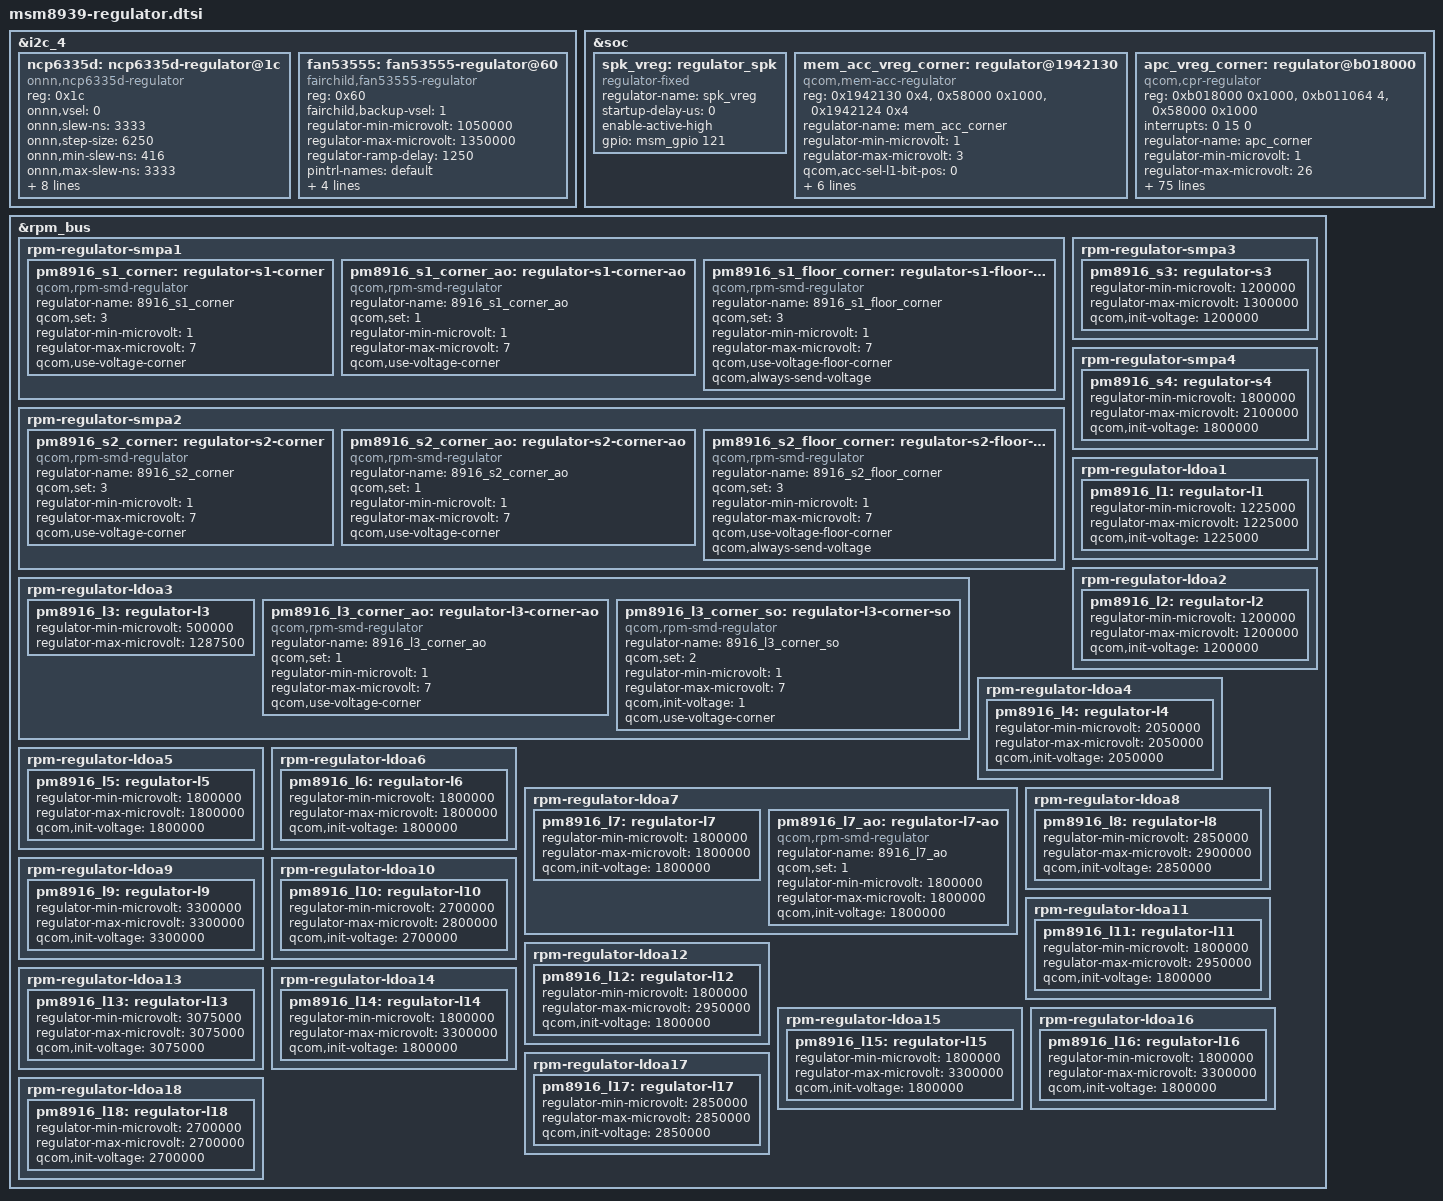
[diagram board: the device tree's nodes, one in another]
/* Copyright (c) 2014, The Linux Foundation. All rights reserved.
 *
 * This program is free software; you can redistribute it and/or modify
 * it under the terms of the GNU General Public License version 2 and
 * only version 2 as published by the Free Software Foundation.
 *
 * This program is distributed in the hope that it will be useful,
 * but WITHOUT ANY WARRANTY; without even the implied warranty of
 * MERCHANTABILITY or FITNESS FOR A PARTICULAR PURPOSE.  See the
 * GNU General Public License for more details.
 */

/* External I2C controlled buck regulators */

&i2c_4 {
	ncp6335d: ncp6335d-regulator@1c {
		compatible = "onnn,ncp6335d-regulator";
		reg = <0x1c>;
		onnn,vsel = <0>;
		onnn,slew-ns = <3333>;
		onnn,step-size = <6250>;
		onnn,min-slew-ns = <416>;
		onnn,max-slew-ns = <3333>;
		regulator-min-microvolt = <1050000>;
		regulator-max-microvolt = <1350000>;
		onnn,min-setpoint = <600000>;
		pintrl-names = "default";
		pinctrl-0 = <&ext_buck_vsel_default>;
		onnn,vsel-gpio = <&msm_gpio 111 1>;
		onnn,discharge-enable;
		onnn,restore-reg;
	};

	fan53555: fan53555-regulator@60 {
		compatible = "fairchild,fan53555-regulator";
		reg = <0x60>;
		fairchild,backup-vsel = <1>;
		regulator-min-microvolt = <1050000>;
		regulator-max-microvolt = <1350000>;
		regulator-ramp-delay = <1250>;
		pintrl-names = "default";
		pinctrl-0 = <&ext_buck_vsel_default>;
		fairchild,vsel-gpio = <&msm_gpio 111 1>;
		fairchild,restore-reg;
		fairchild,disable-suspend;
	};
};

/* Memory accelerator and CPR controlled regulators */

&soc {
	spk_vreg: regulator_spk {
		compatible = "regulator-fixed";
		regulator-name = "spk_vreg";
		startup-delay-us = <0>;
		enable-active-high;
		gpio = <&msm_gpio 121 0>;
	};

	mem_acc_vreg_corner: regulator@1942130 {
		compatible = "qcom,mem-acc-regulator";
		reg = <0x1942130 0x4>, <0x58000 0x1000>, <0x1942124 0x4>;
		reg-names = "acc-sel-l1", "efuse_addr", "acc-l2-custom";
		regulator-name = "mem_acc_corner";
		regulator-min-microvolt = <1>;
		regulator-max-microvolt = <3>;

		qcom,acc-sel-l1-bit-pos = <0>;
		qcom,corner-acc-map = <0 0 1>;
		qcom,l2-acc-custom-data = <0x0 0x0 0x3000>;

		qcom,override-acc-fuse-sel = <0 30 1 1 0>;
		qcom,override-corner-acc-map = <0 1 1>;
		qcom,override-l2-acc-custom-data = <0x0 0x3000 0x3000>;
	};

	apc_vreg_corner: regulator@b018000 {
		compatible = "qcom,cpr-regulator";
		reg = <0xb018000 0x1000>, <0xb011064 4>, <0x58000 0x1000>;
		reg-names = "rbcpr", "rbcpr_clk", "efuse_addr";
		interrupts = <0 15 0>;
		regulator-name = "apc_corner";
		regulator-min-microvolt = <1>;
		regulator-max-microvolt = <26>;

		qcom,cpr-fuse-corners = <3>;
		qcom,cpr-voltage-ceiling = <1050000 1150000 1350000>;
		qcom,cpr-voltage-floor = <1050000 1050000 1137500>;
		vdd-apc-supply = <&ncp6335d>;

		qcom,vdd-mx-corner-map = <4 5 7>;
		qcom,vdd-mx-vmin-method = <4>;
		vdd-mx-supply = <&pm8916_l3_corner_ao>;
		qcom,vdd-mx-vmax = <7>;

		mem-acc-supply = <&mem_acc_vreg_corner>;

		qcom,cpr-ref-clk = <19200>;
		qcom,cpr-timer-delay = <5000>;
		qcom,cpr-timer-cons-up = <0>;
		qcom,cpr-timer-cons-down = <2>;
		qcom,cpr-irq-line = <0>;
		qcom,cpr-step-quotient = <13>;
		qcom,cpr-up-threshold = <0>;
		qcom,cpr-down-threshold = <3>;
		qcom,cpr-idle-clocks = <15>;
		qcom,cpr-gcnt-time = <1>;
		qcom,vdd-apc-step-up-limit = <1>;
		qcom,vdd-apc-step-down-limit = <1>;
		qcom,cpr-apc-volt-step = <6250>;

		qcom,cpr-fuse-row = <27 0>;
		qcom,cpr-fuse-target-quot = <42 24 6>;
		qcom,cpr-fuse-ro-sel = <54 54 54>;
		qcom,cpr-quot-min-diff = <0>;
		qcom,cpr-init-voltage-ref = <1050000 1150000 1350000>;
		qcom,cpr-fuse-init-voltage =
					<27 36 6 0>,
					<27 18 6 0>,
					<27 0 6 0>;
		qcom,cpr-init-voltage-step = <10000>;
		qcom,cpr-scaled-init-voltage-as-ceiling;
		qcom,cpr-corner-map = <1 1 1 2 2 2 2 2 2 2 2 2 2 2 3 3 3 3 3 3
					3 3 3 3 3 3>;
		qcom,cpr-corner-frequency-map =
					<1 200000000>,
					<2 345600000>,
					<3 400000000>,
					<4 422400000>,
					<5 499200000>,
					<6 533330000>,
					<7 652800000>,
					<8 729600000>,
					<9 800000000>,
					<10 806400000>,
					<11 883200000>,
					<12 960000000>,
					<13 1036800000>,
					<14 1113600000>,
					<15 1190400000>,
					<16 1267200000>,
					<17 1344000000>,
					<18 1420800000>,
					<19 1497600000>,
					<20 1536000000>,
					<21 1574400000>,
					<22 1612800000>,
					<23 1632000000>,
					<24 1651200000>,
					<25 1689600000>,
					<26 1708800000>;
		qcom,speed-bin-fuse-sel = <1 34 3 0>;
		qcom,cpr-speed-bin-max-corners =
					<0 0 3 14 17>,
					<0 1 3 14 17>,
					<2 0 3 14 19>,
					<2 1 3 14 19>,
					<4 0 3 14 26>,
					<4 1 3 14 26>,
					<5 0 3 14 24>,
					<5 1 3 14 24>;
		qcom,cpr-quot-adjust-scaling-factor-max = <900>;
		qcom,pvs-version-fuse-sel = <0 45 1 0>;
		qcom,cpr-fuse-version-map =
			<2          0 0xffffffff 0xffffffff
					0xffffffff 0xffffffff>,
			<2          1 0xffffffff 0xffffffff
					0xffffffff 0xffffffff>,
			<0xffffffff 0 0xffffffff 0xffffffff
					0xffffffff 0xffffffff>,
			<0xffffffff 1 0xffffffff 0xffffffff
					0xffffffff 0xffffffff>;
		qcom,cpr-init-voltage-adjustment =
					<0 50000 0>,
					<0 20000 0>,
					<0 50000 0>,
					<0 20000 0>;
		qcom,cpr-quotient-adjustment =
					<0 104  (-41)>,
					<0  41  (-41)>,
					<0 104  (-41)>,
					<0  41  (-41)>;
		qcom,cpr-virtual-corner-quotient-adjustment =
			<0 0 0 (-104) (-104) (-104) (-104) (-104) (-104) (-104)
			 (-104) (-104) (-41) 0 0 0 0 0 0 0 0 72 0 0 0 0>,
			<0 0 0 (-104) (-104) (-104) (-104) (-104) (-104) (-104)
			 (-104) (-41) (-41) 0 0 0 0 0 0 0 0 72 0 0 0 0>,
			<0 0 0 (-104) (-104) (-104) (-104) (-104) (-104) (-104)
			 (-104) (-104) (-41) 0 0 0 0 0 0 0 0 0 0 0 0 0>,
			<0 0 0 (-104) (-104) (-104) (-104) (-104) (-104) (-104)
			 (-104) (-41) (-41) 0 0 0 0 0 0 0 0 0 0 0 0 0>;
		qcom,cpr-virtual-corner-init-voltage-adjustment =
			<0 0 0 0 0 0 0 0 0 0 0 0 0 0 0 0 0 0 0 0 0 35000 0 0 0 0>,
			<0 0 0 0 0 0 0 0 0 0 0 0 0 0 0 0 0 0 0 0 0 35000 0 0 0 0>,
			<0 0 0 0 0 0 0 0 0 0 0 0 0 0 0 0 0 0 0 0 0     0 0 0 0 0>,
			<0 0 0 0 0 0 0 0 0 0 0 0 0 0 0 0 0 0 0 0 0     0 0 0 0 0>;
		qcom,cpr-voltage-floor-override =
			<0xffffffff 0xffffffff 1050000 1050000 1050000
			1050000 1050000 1050000 1050000 1050000 1050000
			1050000 1050000 1050000 1050000 1100000 1137500
			1137500 1137500 1137500 1137500 1137500 1137500
			1137500 1137500 1137500 1137500 1137500>;
		qcom,cpr-enable;
	};
};

/* RPM controlled regulators */

&rpm_bus {
	/* PM8916 S1 VDD_CX for MODEM/NAV/Crypto/MODEM Q6 */
	rpm-regulator-smpa1 {
		status = "okay";
		pm8916_s1_corner: regulator-s1-corner {
			compatible = "qcom,rpm-smd-regulator";
			regulator-name = "8916_s1_corner";
			qcom,set = <3>;
			regulator-min-microvolt = <1>;
			regulator-max-microvolt = <7>;
			qcom,use-voltage-corner;
		};
		pm8916_s1_corner_ao: regulator-s1-corner-ao {
			compatible = "qcom,rpm-smd-regulator";
			regulator-name = "8916_s1_corner_ao";
			qcom,set = <1>;
			regulator-min-microvolt = <1>;
			regulator-max-microvolt = <7>;
			qcom,use-voltage-corner;
		};
		pm8916_s1_floor_corner: regulator-s1-floor-corner {
			compatible = "qcom,rpm-smd-regulator";
			regulator-name = "8916_s1_floor_corner";
			qcom,set = <3>;
			regulator-min-microvolt = <1>;
			regulator-max-microvolt = <7>;
			qcom,use-voltage-floor-corner;
			qcom,always-send-voltage;
		};
	};

	/* PM8916 S2 VDD_CX for Venus/TOP/GFX/Pronto/MDSS*/
	rpm-regulator-smpa2 {
		status = "okay";
		pm8916_s2_corner: regulator-s2-corner {
			compatible = "qcom,rpm-smd-regulator";
			regulator-name = "8916_s2_corner";
			qcom,set = <3>;
			regulator-min-microvolt = <1>;
			regulator-max-microvolt = <7>;
			qcom,use-voltage-corner;
		};
		pm8916_s2_corner_ao: regulator-s2-corner-ao {
			compatible = "qcom,rpm-smd-regulator";
			regulator-name = "8916_s2_corner_ao";
			qcom,set = <1>;
			regulator-min-microvolt = <1>;
			regulator-max-microvolt = <7>;
			qcom,use-voltage-corner;
		};
		pm8916_s2_floor_corner: regulator-s2-floor-corner {
			compatible = "qcom,rpm-smd-regulator";
			regulator-name = "8916_s2_floor_corner";
			qcom,set = <3>;
			regulator-min-microvolt = <1>;
			regulator-max-microvolt = <7>;
			qcom,use-voltage-floor-corner;
			qcom,always-send-voltage;
		};
	};

	rpm-regulator-smpa3 {
		status = "okay";
		pm8916_s3: regulator-s3 {
			regulator-min-microvolt = <1200000>;
			regulator-max-microvolt = <1300000>;
			qcom,init-voltage = <1200000>;
			status = "okay";
		};
	};

	rpm-regulator-smpa4 {
		status = "okay";
		pm8916_s4: regulator-s4 {
			regulator-min-microvolt = <1800000>;
			regulator-max-microvolt = <2100000>;
			qcom,init-voltage = <1800000>;
			status = "okay";
		};
	};

	rpm-regulator-ldoa1 {
		status = "okay";
		pm8916_l1: regulator-l1 {
			regulator-min-microvolt = <1225000>;
			regulator-max-microvolt = <1225000>;
			qcom,init-voltage = <1225000>;
			status = "okay";
		};
	};

	rpm-regulator-ldoa2 {
		status = "okay";
		pm8916_l2: regulator-l2 {
			regulator-min-microvolt = <1200000>;
			regulator-max-microvolt = <1200000>;
			qcom,init-voltage = <1200000>;
			status = "okay";
		};
	};

	/* PM8916 L3 VDD_MX supply */
	rpm-regulator-ldoa3 {
		status = "okay";
		pm8916_l3: regulator-l3 {
			regulator-min-microvolt = <500000>;
			regulator-max-microvolt = <1287500>;
			status = "okay";
		};

		pm8916_l3_corner_ao: regulator-l3-corner-ao {
			compatible = "qcom,rpm-smd-regulator";
			regulator-name = "8916_l3_corner_ao";
			qcom,set = <1>;
			regulator-min-microvolt = <1>;
			regulator-max-microvolt = <7>;
			qcom,use-voltage-corner;
		};

		pm8916_l3_corner_so: regulator-l3-corner-so {
			compatible = "qcom,rpm-smd-regulator";
			regulator-name = "8916_l3_corner_so";
			qcom,set = <2>;
			regulator-min-microvolt = <1>;
			regulator-max-microvolt = <7>;
			qcom,init-voltage = <1>;
			qcom,use-voltage-corner;
		};
	};

	rpm-regulator-ldoa4 {
		status = "okay";
		pm8916_l4: regulator-l4 {
			regulator-min-microvolt = <2050000>;
			regulator-max-microvolt = <2050000>;
			qcom,init-voltage = <2050000>;
			status = "okay";
		};
	};

	rpm-regulator-ldoa5 {
		status = "okay";
		pm8916_l5: regulator-l5 {
			regulator-min-microvolt = <1800000>;
			regulator-max-microvolt = <1800000>;
			qcom,init-voltage = <1800000>;
			status = "okay";
		};
	};

	rpm-regulator-ldoa6 {
		status = "okay";
		pm8916_l6: regulator-l6 {
			regulator-min-microvolt = <1800000>;
			regulator-max-microvolt = <1800000>;
			qcom,init-voltage = <1800000>;
			status = "okay";
		};
	};

	rpm-regulator-ldoa7 {
		status = "okay";
		pm8916_l7: regulator-l7 {
			regulator-min-microvolt = <1800000>;
			regulator-max-microvolt = <1800000>;
			qcom,init-voltage = <1800000>;
			status = "okay";
		};

		pm8916_l7_ao: regulator-l7-ao {
			compatible = "qcom,rpm-smd-regulator";
			regulator-name = "8916_l7_ao";
			qcom,set = <1>;
			regulator-min-microvolt = <1800000>;
			regulator-max-microvolt = <1800000>;
			qcom,init-voltage = <1800000>;
		};
	};

	rpm-regulator-ldoa8 {
		status = "okay";
		pm8916_l8: regulator-l8 {
			regulator-min-microvolt = <2850000>;
			regulator-max-microvolt = <2900000>;
			qcom,init-voltage = <2850000>;
			status = "okay";
		};
	};

	rpm-regulator-ldoa9 {
		status = "okay";
		pm8916_l9: regulator-l9 {
			regulator-min-microvolt = <3300000>;
			regulator-max-microvolt = <3300000>;
			qcom,init-voltage = <3300000>;
			status = "okay";
		};
	};

	rpm-regulator-ldoa10 {
		status = "okay";
		pm8916_l10: regulator-l10 {
			regulator-min-microvolt = <2700000>;
			regulator-max-microvolt = <2800000>;
			qcom,init-voltage = <2700000>;
			status = "okay";
		};
	};

	rpm-regulator-ldoa11 {
		status = "okay";
		pm8916_l11: regulator-l11 {
			regulator-min-microvolt = <1800000>;
			regulator-max-microvolt = <2950000>;
			qcom,init-voltage = <1800000>;
			status = "okay";
		};
	};

	rpm-regulator-ldoa12 {
		status = "okay";
		pm8916_l12: regulator-l12 {
			regulator-min-microvolt = <1800000>;
			regulator-max-microvolt = <2950000>;
			qcom,init-voltage = <1800000>;
			status = "okay";
		};
	};

	rpm-regulator-ldoa13 {
		status = "okay";
		pm8916_l13: regulator-l13 {
			regulator-min-microvolt = <3075000>;
			regulator-max-microvolt = <3075000>;
			qcom,init-voltage = <3075000>;
			status = "okay";
		};
	};

	rpm-regulator-ldoa14 {
		status = "okay";
		pm8916_l14: regulator-l14 {
			regulator-min-microvolt = <1800000>;
			regulator-max-microvolt = <3300000>;
			qcom,init-voltage = <1800000>;
			status = "okay";
		};
	};

	rpm-regulator-ldoa15 {
		status = "okay";
		pm8916_l15: regulator-l15 {
			regulator-min-microvolt = <1800000>;
			regulator-max-microvolt = <3300000>;
			qcom,init-voltage = <1800000>;
			status = "okay";
		};
	};

	rpm-regulator-ldoa16 {
		status = "okay";
		pm8916_l16: regulator-l16 {
			regulator-min-microvolt = <1800000>;
			regulator-max-microvolt = <3300000>;
			qcom,init-voltage = <1800000>;
			status = "okay";
		};
	};

	rpm-regulator-ldoa17 {
		status = "okay";
		pm8916_l17: regulator-l17 {
			regulator-min-microvolt = <2850000>;
			regulator-max-microvolt = <2850000>;
			qcom,init-voltage = <2850000>;
			status = "okay";
		};
	};

	rpm-regulator-ldoa18 {
		status = "okay";
		pm8916_l18: regulator-l18 {
			regulator-min-microvolt = <2700000>;
			regulator-max-microvolt = <2700000>;
			qcom,init-voltage = <2700000>;
			status = "okay";
		};
	};
};
